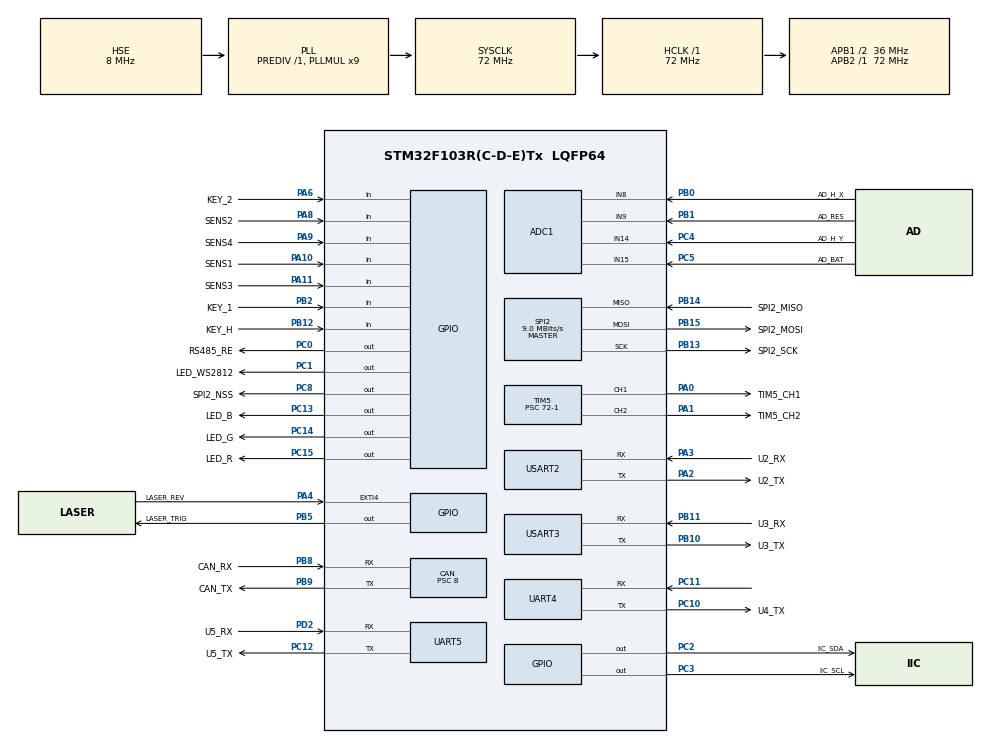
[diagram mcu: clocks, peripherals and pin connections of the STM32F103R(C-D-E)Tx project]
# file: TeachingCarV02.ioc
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ADC1.Channel-0\#ChannelRegularConversion=ADC_CHANNEL_8
ADC1.Channel-1\#ChannelRegularConversion=ADC_CHANNEL_9
ADC1.Channel-2\#ChannelRegularConversion=ADC_CHANNEL_14
ADC1.Channel-3\#ChannelRegularConversion=ADC_CHANNEL_15
ADC1.ContinuousConvMode=ENABLE
ADC1.NbrOfConversion=4
ADC1.NbrOfConversionFlag=1
ADC1.Rank-0\#ChannelRegularConversion=1
ADC1.Rank-1\#ChannelRegularConversion=2
ADC1.Rank-2\#ChannelRegularConversion=3
ADC1.Rank-3\#ChannelRegularConversion=4
ADC1.SamplingTime-0\#ChannelRegularConversion=ADC_SAMPLETIME_239CYCLES_5
ADC1.SamplingTime-1\#ChannelRegularConversion=ADC_SAMPLETIME_239CYCLES_5
ADC1.SamplingTime-2\#ChannelRegularConversion=ADC_SAMPLETIME_239CYCLES_5
ADC1.SamplingTime-3\#ChannelRegularConversion=ADC_SAMPLETIME_239CYCLES_5
ADC1.master=1
CAN.ABOM=ENABLE
CAN.AWUM=ENABLE
CAN.BS1=CAN_BS1_5TQ
CAN.BS2=CAN_BS2_3TQ
CAN.CalculateBaudRate=500000
CAN.CalculateTimeBit=2000
CAN.CalculateTimeQuantum=222.22222222222223
CAN.NART=ENABLE
CAN.Prescaler=8
Dma.ADC1.0.Direction=DMA_PERIPH_TO_MEMORY
Dma.ADC1.0.Instance=DMA1_Channel1
Dma.ADC1.0.MemDataAlignment=DMA_MDATAALIGN_HALFWORD
Dma.ADC1.0.MemInc=DMA_MINC_ENABLE
Dma.ADC1.0.Mode=DMA_CIRCULAR
Dma.ADC1.0.PeriphDataAlignment=DMA_PDATAALIGN_HALFWORD
Dma.ADC1.0.PeriphInc=DMA_PINC_DISABLE
Dma.ADC1.0.Priority=DMA_PRIORITY_LOW
Dma.Request0=ADC1
Dma.Request1=USART2_RX
Dma.Request2=USART2_TX
Dma.Request3=USART3_RX
Dma.Request4=USART3_TX
Dma.Request5=UART4_RX
Dma.Request6=UART4_TX
Dma.UART4_RX.5.Direction=DMA_PERIPH_TO_MEMORY
Dma.UART4_RX.5.Instance=DMA2_Channel3
Dma.UART4_RX.5.MemDataAlignment=DMA_MDATAALIGN_BYTE
Dma.UART4_RX.5.MemInc=DMA_MINC_ENABLE
Dma.UART4_RX.5.Mode=DMA_CIRCULAR
Dma.UART4_RX.5.PeriphDataAlignment=DMA_PDATAALIGN_BYTE
Dma.UART4_RX.5.PeriphInc=DMA_PINC_DISABLE
Dma.UART4_RX.5.Priority=DMA_PRIORITY_LOW
Dma.UART4_TX.6.Direction=DMA_MEMORY_TO_PERIPH
Dma.UART4_TX.6.Instance=DMA2_Channel5
Dma.UART4_TX.6.MemDataAlignment=DMA_MDATAALIGN_BYTE
Dma.UART4_TX.6.MemInc=DMA_MINC_ENABLE
Dma.UART4_TX.6.Mode=DMA_NORMAL
Dma.UART4_TX.6.PeriphDataAlignment=DMA_PDATAALIGN_BYTE
Dma.UART4_TX.6.PeriphInc=DMA_PINC_DISABLE
Dma.UART4_TX.6.Priority=DMA_PRIORITY_LOW
Dma.USART2_RX.1.Direction=DMA_PERIPH_TO_MEMORY
Dma.USART2_RX.1.Instance=DMA1_Channel6
Dma.USART2_RX.1.MemDataAlignment=DMA_MDATAALIGN_BYTE
Dma.USART2_RX.1.MemInc=DMA_MINC_ENABLE
Dma.USART2_RX.1.Mode=DMA_CIRCULAR
Dma.USART2_RX.1.PeriphDataAlignment=DMA_PDATAALIGN_BYTE
Dma.USART2_RX.1.PeriphInc=DMA_PINC_DISABLE
Dma.USART2_RX.1.Priority=DMA_PRIORITY_LOW
Dma.USART2_TX.2.Direction=DMA_MEMORY_TO_PERIPH
Dma.USART2_TX.2.Instance=DMA1_Channel7
Dma.USART2_TX.2.MemDataAlignment=DMA_MDATAALIGN_BYTE
Dma.USART2_TX.2.MemInc=DMA_MINC_ENABLE
Dma.USART2_TX.2.Mode=DMA_NORMAL
Dma.USART2_TX.2.PeriphDataAlignment=DMA_PDATAALIGN_BYTE
Dma.USART2_TX.2.PeriphInc=DMA_PINC_DISABLE
Dma.USART2_TX.2.Priority=DMA_PRIORITY_LOW
Dma.USART3_RX.3.Direction=DMA_PERIPH_TO_MEMORY
Dma.USART3_RX.3.Instance=DMA1_Channel3
Dma.USART3_RX.3.MemDataAlignment=DMA_MDATAALIGN_BYTE
Dma.USART3_RX.3.MemInc=DMA_MINC_ENABLE
Dma.USART3_RX.3.Mode=DMA_CIRCULAR
Dma.USART3_RX.3.PeriphDataAlignment=DMA_PDATAALIGN_BYTE
Dma.USART3_RX.3.PeriphInc=DMA_PINC_DISABLE
Dma.USART3_RX.3.Priority=DMA_PRIORITY_LOW
Dma.USART3_TX.4.Direction=DMA_MEMORY_TO_PERIPH
Dma.USART3_TX.4.Instance=DMA1_Channel2
Dma.USART3_TX.4.MemDataAlignment=DMA_MDATAALIGN_BYTE
Dma.USART3_TX.4.MemInc=DMA_MINC_ENABLE
Dma.USART3_TX.4.Mode=DMA_NORMAL
Dma.USART3_TX.4.PeriphDataAlignment=DMA_PDATAALIGN_BYTE
Dma.USART3_TX.4.PeriphInc=DMA_PINC_DISABLE
Dma.USART3_TX.4.Priority=DMA_PRIORITY_LOW
FREERTOS.Tasks01=TaskLow,8,128,StartTaskLow,As weak,NULL,Dynamic,NULL,NULL;TaskHigh,40,128,StartTaskHigh,As weak,NULL,Dynamic,NULL,NULL;TaskMid,24,128,StartTaskMid,As weak,NULL,Dynamic,NULL,NULL
Mcu.Family=STM32F1
Mcu.Name=STM32F103R(C-D-E)Tx
Mcu.Package=LQFP64
NVIC.DMA1_Channel1_IRQn=true\:5\:0\:false\:false\:true\:true\:false\:true\:true
NVIC.DMA1_Channel2_IRQn=true\:5\:0\:false\:false\:true\:true\:false\:true\:true
NVIC.DMA1_Channel3_IRQn=true\:5\:0\:false\:false\:true\:true\:false\:true\:true
NVIC.DMA1_Channel6_IRQn=true\:5\:0\:false\:false\:true\:true\:false\:true\:true
NVIC.DMA1_Channel7_IRQn=true\:5\:0\:false\:false\:true\:true\:false\:true\:true
NVIC.DMA2_Channel3_IRQn=true\:5\:0\:false\:false\:true\:true\:false\:true\:true
NVIC.DMA2_Channel4_5_IRQn=true\:5\:0\:false\:false\:true\:true\:false\:true\:true
NVIC.EXTI4_IRQn=true\:7\:0\:true\:false\:true\:true\:true\:true\:true
NVIC.PriorityGroup=NVIC_PRIORITYGROUP_4
NVIC.TIM1_UP_IRQn=true\:6\:0\:true\:false\:true\:true\:true\:true\:true
NVIC.TIM2_IRQn=true\:6\:0\:true\:false\:true\:true\:true\:true\:true
NVIC.TIM7_IRQn=true\:15\:0\:false\:false\:true\:false\:false\:true\:true
NVIC.TimeBase=TIM7_IRQn
NVIC.TimeBaseIP=TIM7
NVIC.UART4_IRQn=true\:6\:0\:true\:false\:true\:true\:true\:true\:true
NVIC.UART5_IRQn=true\:6\:0\:true\:false\:true\:true\:true\:true\:true
NVIC.USART2_IRQn=true\:6\:0\:true\:false\:true\:true\:true\:true\:true
NVIC.USART3_IRQn=true\:6\:0\:true\:false\:true\:true\:true\:true\:true
NVIC.USB_LP_CAN1_RX0_IRQn=true\:6\:0\:true\:false\:true\:true\:true\:true\:true
PA0-WKUP.GPIO_Label=TIM5_CH1
PA0-WKUP.Signal=S_TIM5_CH1
PA1.GPIO_Label=TIM5_CH2
PA1.Signal=S_TIM5_CH2
PA10.GPIO_Label=SENS1
PA10.GPIO_PuPd=GPIO_PULLUP
PA10.Signal=GPIO_Input
PA11.GPIO_Label=SENS3
PA11.GPIO_PuPd=GPIO_PULLUP
PA11.Signal=GPIO_Input
PA13.Mode=Serial_Wire
PA13.Signal=SYS_JTMS-SWDIO
PA14.Mode=Serial_Wire
PA14.Signal=SYS_JTCK-SWCLK
PA2.GPIO_Label=U2_TX
PA2.Mode=Asynchronous
PA2.Signal=USART2_TX
PA3.GPIO_Label=U2_RX
PA3.Mode=Asynchronous
PA3.Signal=USART2_RX
PA4.GPIO_Label=LASER_REV
PA4.GPIO_ModeDefaultEXTI=GPIO_MODE_IT_FALLING
PA4.GPIO_PuPd=GPIO_PULLUP
PA4.Signal=GPXTI4
PA6.GPIO_Label=KEY_2
PA6.GPIO_PuPd=GPIO_PULLUP
PA6.Signal=GPIO_Input
PA8.GPIO_Label=SENS2
PA8.GPIO_PuPd=GPIO_PULLUP
PA8.Signal=GPIO_Input
PA9.GPIO_Label=SENS4
PA9.GPIO_PuPd=GPIO_PULLUP
PA9.Signal=GPIO_Input
PB0.GPIO_Label=AD_H_X
PB0.Signal=ADCx_IN8
PB1.GPIO_Label=AD_RES
PB1.Signal=ADCx_IN9
PB10.GPIO_Label=U3_TX
PB10.Mode=Asynchronous
PB10.Signal=USART3_TX
PB11.GPIO_Label=U3_RX
PB11.Mode=Asynchronous
PB11.Signal=USART3_RX
PB12.GPIO_Label=KEY_H
PB12.GPIO_PuPd=GPIO_PULLUP
PB12.Signal=GPIO_Input
PB13.GPIO_Label=SPI2_SCK
PB13.Mode=Full_Duplex_Master
PB13.Signal=SPI2_SCK
PB14.GPIO_Label=SPI2_MISO
PB14.Mode=Full_Duplex_Master
PB14.Signal=SPI2_MISO
PB15.GPIO_Label=SPI2_MOSI
PB15.Mode=Full_Duplex_Master
PB15.Signal=SPI2_MOSI
PB2.GPIO_Label=KEY_1
PB2.GPIO_PuPd=GPIO_PULLUP
PB2.Signal=GPIO_Input
PB5.GPIO_Label=LASER_TRIG
PB5.Signal=GPIO_Output
PB7.GPIO_Label=U1_RX
PB7.Signal=USART1_RX
PB8.GPIO_Label=CAN_RX
PB8.Mode=CAN_Activate
PB8.Signal=CAN_RX
PB9.GPIO_Label=CAN_TX
PB9.Mode=CAN_Activate
PB9.Signal=CAN_TX
PC0.GPIO_Label=RS485_RE
PC0.Signal=GPIO_Output
PC1.GPIO_Label=LED_WS2812
PC1.GPIO_PuPd=GPIO_NOPULL
PC1.GPIO_Speed=GPIO_SPEED_FREQ_HIGH
PC1.PinState=GPIO_PIN_SET
PC1.Signal=GPIO_Output
PC10.GPIO_Label=U4_TX
PC10.Mode=Asynchronous
PC10.Signal=UART4_TX
PC11.Mode=Asynchronous
PC11.Signal=UART4_RX
PC12.GPIO_Label=U5_TX
PC12.Mode=Asynchronous
PC12.Signal=UART5_TX
PC13-TAMPER-RTC.GPIO_Label=LED_B
PC13-TAMPER-RTC.GPIO_PuPd=GPIO_NOPULL
PC13-TAMPER-RTC.PinState=GPIO_PIN_SET
PC13-TAMPER-RTC.Signal=GPIO_Output
PC14-OSC32_IN.GPIO_Label=LED_G
PC14-OSC32_IN.GPIO_PuPd=GPIO_NOPULL
PC14-OSC32_IN.PinState=GPIO_PIN_SET
PC14-OSC32_IN.Signal=GPIO_Output
PC15-OSC32_OUT.GPIO_Label=LED_R
PC15-OSC32_OUT.GPIO_PuPd=GPIO_NOPULL
PC15-OSC32_OUT.PinState=GPIO_PIN_SET
PC15-OSC32_OUT.Signal=GPIO_Output
PC2.GPIO_Label=IIC_SDA
PC2.GPIO_ModeDefaultOutputPP=GPIO_MODE_OUTPUT_OD
PC2.GPIO_PuPd=GPIO_NOPULL
PC2.GPIO_Speed=GPIO_SPEED_FREQ_MEDIUM
PC2.Signal=GPIO_Output
PC3.GPIO_Label=IIC_SCL
PC3.GPIO_Speed=GPIO_SPEED_FREQ_MEDIUM
PC3.Signal=GPIO_Output
PC4.GPIO_Label=AD_H_Y
PC4.Signal=ADCx_IN14
PC5.GPIO_Label=AD_BAT
PC5.Signal=ADCx_IN15
PC8.GPIO_Label=SPI2_NSS
PC8.GPIO_Speed=GPIO_SPEED_FREQ_HIGH
PC8.Signal=GPIO_Output
PD0-OSC_IN.Mode=HSE-External-Oscillator
PD0-OSC_IN.Signal=RCC_OSC_IN
PD1-OSC_OUT.Mode=HSE-External-Oscillator
PD1-OSC_OUT.Signal=RCC_OSC_OUT
PD2.GPIO_Label=U5_RX
PD2.Mode=Asynchronous
PD2.Signal=UART5_RX
ProjectManager.HeapSize=0x200
ProjectManager.StackSize=0x400
ProjectManager.TargetToolchain=MDK-ARM V5.32
RCC.ADCPresc=RCC_ADCPCLK2_DIV6
RCC.AHBFreq_Value=72000000
RCC.APB1CLKDivider=RCC_HCLK_DIV2
RCC.APB1Freq_Value=36000000
RCC.APB1TimFreq_Value=72000000
RCC.APB2Freq_Value=72000000
RCC.APB2TimFreq_Value=72000000
RCC.HCLKFreq_Value=72000000
RCC.PLLMUL=RCC_PLL_MUL9
RCC.PLLSourceVirtual=RCC_PLLSOURCE_HSE
RCC.SYSCLKFreq_VALUE=72000000
RCC.SYSCLKSource=RCC_SYSCLKSOURCE_PLLCLK
RCC.USBFreq_Value=72000000
SH.ADCx_IN14.0=ADC1_IN14,IN14
SH.ADCx_IN15.0=ADC1_IN15,IN15
SH.ADCx_IN8.0=ADC1_IN8,IN8
SH.ADCx_IN9.0=ADC1_IN9,IN9
SH.S_TIM5_CH1.0=TIM5_CH1,PWM Generation1 CH1
SH.S_TIM5_CH2.0=TIM5_CH2,PWM Generation2 CH2
SPI2.BaudRatePrescaler=SPI_BAUDRATEPRESCALER_4
SPI2.CalculateBaudRate=9.0 MBits/s
SPI2.Direction=SPI_DIRECTION_2LINES
SPI2.Mode=SPI_MODE_MASTER
SPI2.VirtualType=VM_MASTER
TIM1.AutoReloadPreload=TIM_AUTORELOAD_PRELOAD_ENABLE
TIM1.Period=100
TIM1.Prescaler=72-1
TIM2.AutoReloadPreload=TIM_AUTORELOAD_PRELOAD_ENABLE
TIM2.Period=1000
TIM2.Prescaler=72-1
TIM5.AutoReloadPreload=TIM_AUTORELOAD_PRELOAD_ENABLE
TIM5.Channel-PWM\ Generation1\ CH1=TIM_CHANNEL_1
TIM5.Channel-PWM\ Generation2\ CH2=TIM_CHANNEL_2
TIM5.Period=20000
TIM5.Prescaler=72-1
TIM8.Prescaler=9-1
UART4.VirtualMode=Asynchronous
UART5.VirtualMode=Asynchronous
USART2.VirtualMode=VM_ASYNC
USART3.VirtualMode=VM_ASYNC
VP_FREERTOS_VS_CMSIS_V2.Mode=CMSIS_V2
VP_SYS_VS_tim7.Mode=TIM7
VP_TIM1_VS_ClockSourceINT.Mode=Internal
VP_TIM2_VS_ClockSourceINT.Mode=Internal
VP_TIM5_VS_ClockSourceINT.Mode=Internal
VP_TIM8_VS_ClockSourceINT.Mode=Internal
board=custom

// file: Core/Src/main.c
/* USER CODE BEGIN Header */
/**
  ******************************************************************************
  * @file           : main.c
  * @brief          : Main program body
  ******************************************************************************
  * @attention
  *
  * Copyright (c) 2026 STMicroelectronics.
  * All rights reserved.
  *
  * This software is licensed under terms that can be found in the LICENSE file
  * in the root directory of this software component.
  * If no LICENSE file comes with this software, it is provided AS-IS.
  *
  ******************************************************************************
  */
/* USER CODE END Header */
#include "main.h"
#include "cmsis_os.h"
#include "adc.h"
#include "can.h"
#include "dma.h"
#include "spi.h"
#include "tim.h"
#include "usart.h"
#include "gpio.h"

/* USER CODE BEGIN Includes */
#include "app_chassis_link.h"
/* USER CODE END Includes */

/* USER CODE BEGIN PV */
volatile MID_CANopenStatusTypeDef g_chassisLinkInitStatus = MID_CANOPEN_ERROR; /**< 底盘链路初始化返回值，供调试器观察。 */
/* USER CODE END PV */

void SystemClock_Config(void);
void MX_FREERTOS_Init(void);

int main(void)
{

  /* MCU Configuration--------------------------------------------------------*/

  /* Reset of all peripherals, Initializes the Flash interface and the Systick. */
  HAL_Init();

  /* Configure the system clock */
  SystemClock_Config();

  /* Initialize all configured peripherals */
  MX_GPIO_Init();
  MX_DMA_Init();
  MX_ADC1_Init();
  MX_TIM2_Init();
  /* HAL 毫秒时基由 HAL_InitTick 启动的 TIM7 独立提供，应用定时器 TIM2 不再兼作时基。 */
  MX_USART2_UART_Init();
  MX_USART3_UART_Init();
  MX_SPI2_Init();
  MX_UART4_Init();
  MX_UART5_Init();
  MX_CAN_Init();
  MX_TIM1_Init();
  MX_TIM5_Init();
  MX_TIM8_Init();
  /* USER CODE BEGIN 2 */
  /* 底盘链路初始化, 内部按顺序完成 CANopen 初始化、节点注册、静态二值信号量创建、驱动器使能与串口接收启动。 */
  g_chassisLinkInitStatus = APP_ChassisLink_Init();
#if (CHASSIS_LINK_POWER_MONITOR_ENABLE == 1U)
  /* 电源监视初始化, 内部完成 ADC 校准启动、DMA 循环采样与点阵屏初始化。 */
  APP_PowerMonitor_Init();
#endif
  /* USER CODE END 2 */

  /* Init scheduler */
  osKernelInitialize();  /* Call init function for freertos objects (in cmsis_os2.c) */
  MX_FREERTOS_Init();

  /* Start scheduler */
  osKernelStart();

  /* We should never get here as control is now taken by the scheduler */

  /* Infinite loop */
  while (1)
  {

  }
}

void SystemClock_Config(void)
{
  RCC_OscInitTypeDef RCC_OscInitStruct = {0};
  RCC_ClkInitTypeDef RCC_ClkInitStruct = {0};
  RCC_PeriphCLKInitTypeDef PeriphClkInit = {0};

  /** Initializes the RCC Oscillators according to the specified parameters
  * in the RCC_OscInitTypeDef structure.
  */
  RCC_OscInitStruct.OscillatorType = RCC_OSCILLATORTYPE_HSE;
  RCC_OscInitStruct.HSEState = RCC_HSE_ON;
  RCC_OscInitStruct.HSEPredivValue = RCC_HSE_PREDIV_DIV1;
  RCC_OscInitStruct.HSIState = RCC_HSI_ON;
  RCC_OscInitStruct.PLL.PLLState = RCC_PLL_ON;
  RCC_OscInitStruct.PLL.PLLSource = RCC_PLLSOURCE_HSE;
  RCC_OscInitStruct.PLL.PLLMUL = RCC_PLL_MUL9;
  if (HAL_RCC_OscConfig(&RCC_OscInitStruct) != HAL_OK)
  {
    Error_Handler();
  }

  /** Initializes the CPU, AHB and APB buses clocks
  */
  RCC_ClkInitStruct.ClockType = RCC_CLOCKTYPE_HCLK|RCC_CLOCKTYPE_SYSCLK
                              |RCC_CLOCKTYPE_PCLK1|RCC_CLOCKTYPE_PCLK2;
  RCC_ClkInitStruct.SYSCLKSource = RCC_SYSCLKSOURCE_PLLCLK;
  RCC_ClkInitStruct.AHBCLKDivider = RCC_SYSCLK_DIV1;
  RCC_ClkInitStruct.APB1CLKDivider = RCC_HCLK_DIV2;
  RCC_ClkInitStruct.APB2CLKDivider = RCC_HCLK_DIV1;

  if (HAL_RCC_ClockConfig(&RCC_ClkInitStruct, FLASH_LATENCY_2) != HAL_OK)
  {
    Error_Handler();
  }
  PeriphClkInit.PeriphClockSelection = RCC_PERIPHCLK_ADC;
  PeriphClkInit.AdcClockSelection = RCC_ADCPCLK2_DIV6;
  if (HAL_RCCEx_PeriphCLKConfig(&PeriphClkInit) != HAL_OK)
  {
    Error_Handler();
  }
}

/**
  * @brief  在 TIM7 周期中断中维护 HAL 毫秒时基。
  * @param  htim  定时器句柄。
  * @retval None
  * @note   TIM7 由 stm32f1xx_hal_timebase_tim.c 的 HAL_InitTick 配置并启动，1 毫秒一拍。
  *         此回调只允许 TIM7 推进 HAL 毫秒时基；若让其它定时器也调用 HAL_IncTick，
  *         uwTick 会按多个定时器的频率累加，所有以毫秒为单位的超时都会成倍缩短。
  */
void HAL_TIM_PeriodElapsedCallback(TIM_HandleTypeDef *htim)
{
  if (htim->Instance == TIM7)
  {
    HAL_IncTick();
  }
}

void Error_Handler(void)
{
  __disable_irq();
  while (1)
  {
  }
}

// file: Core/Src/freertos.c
/* USER CODE BEGIN Header */
/**
  ******************************************************************************
  * File Name          : freertos.c
  * Description        : Code for freertos applications
  ******************************************************************************
  * @attention
  *
  * Copyright (c) 2026 STMicroelectronics.
  * All rights reserved.
  *
  * This software is licensed under terms that can be found in the LICENSE file
  * in the root directory of this software component.
  * If no LICENSE file comes with this software, it is provided AS-IS.
  *
  ******************************************************************************
  */
/* USER CODE END Header */

#include "FreeRTOS.h"
#include "task.h"
#include "main.h"
#include "cmsis_os.h"

/* USER CODE BEGIN Includes */
#include "app_chassis_link.h"
#include "chassis_link_config.h"
/* USER CODE END Includes */

/* Definitions for TaskLow */
osThreadId_t TaskLowHandle;
const osThreadAttr_t TaskLow_attributes = {
  .name = "TaskLow",
  .stack_size = 128 * 4,
  .priority = (osPriority_t) osPriorityLow,
};
/* Definitions for TaskHigh */
osThreadId_t TaskHighHandle;
const osThreadAttr_t TaskHigh_attributes = {
  .name = "TaskHigh",
  .stack_size = CHASSIS_LINK_TASK_STACK_BYTES,
  .priority = (osPriority_t) osPriorityHigh,
};
/* Definitions for TaskMid */
osThreadId_t TaskMidHandle;
const osThreadAttr_t TaskMid_attributes = {
  .name = "TaskMid",
  .stack_size = 128 * 4,
  .priority = (osPriority_t) osPriorityNormal,
};

void StartTaskLow(void *argument);
void StartTaskHigh(void *argument);
void StartTaskMid(void *argument);

void MX_FREERTOS_Init(void); /* (MISRA C 2004 rule 8.1) */

void MX_FREERTOS_Init(void) {

  /* Create the thread(s) */
  /* creation of TaskLow */
  TaskLowHandle = osThreadNew(StartTaskLow, NULL, &TaskLow_attributes);

  /* creation of TaskHigh */
  TaskHighHandle = osThreadNew(StartTaskHigh, NULL, &TaskHigh_attributes);

  /* creation of TaskMid */
  TaskMidHandle = osThreadNew(StartTaskMid, NULL, &TaskMid_attributes);

}

__weak void StartTaskLow(void *argument)
{
  for(;;)
  {
    osDelay(1);
  }
}

__weak void StartTaskHigh(void *argument)
{
  /* USER CODE BEGIN StartTaskHigh */
  /* 底盘链路任务自带死循环，内部完成等待信号量、解析帧与转速下发。 */
  APP_ChassisLink_Task(argument);
  /* USER CODE END StartTaskHigh */
}

__weak void StartTaskMid(void *argument)
{
  for(;;)
  {
    osDelay(1);
  }
}
